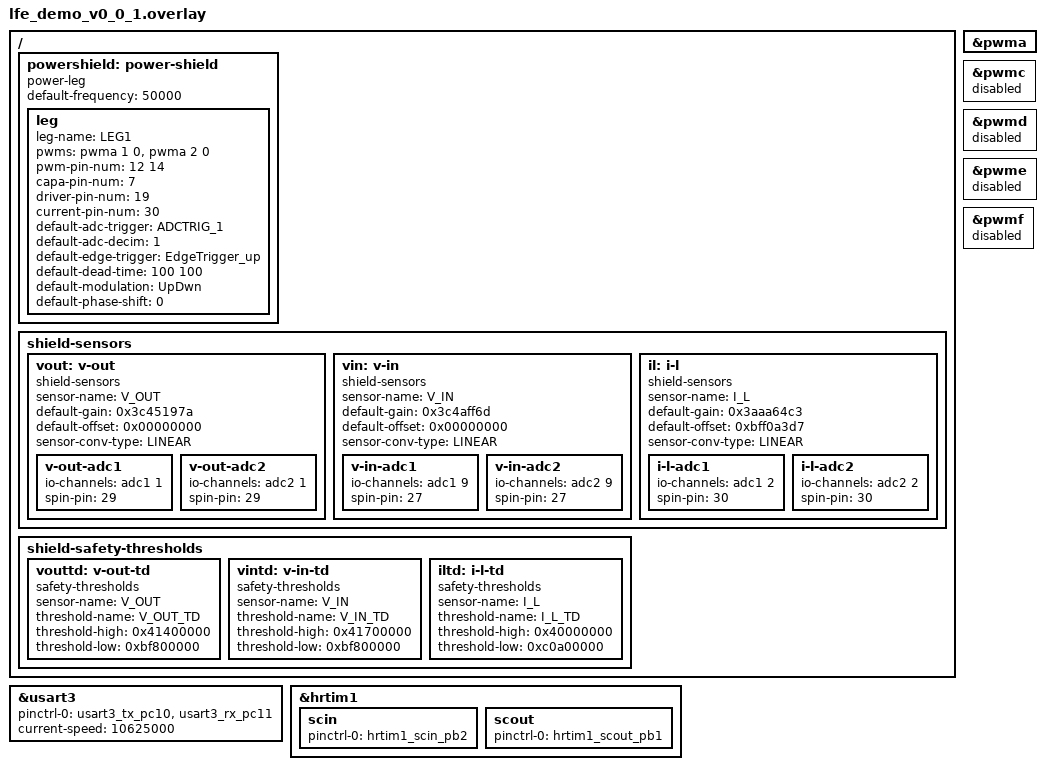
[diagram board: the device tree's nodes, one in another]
/*
 * Copyright (c) 2023-2024 OwnTech.
 *
 * SPDX-License-Identifier: LGPL-2.1
 */

/ {
	powershield: power-shield{
        compatible = "power-leg";
        default-frequency = <50000>;
        leg: leg{
            leg-name = "LEG1";
			pwms = <&pwma 1 0>, <&pwma 2 0>;
            pwm-pin-num = <12 14>;
            capa-pin-num = <7>;
            driver-pin-num = <19>;
            current-pin-num = <30>;
            default-adc-trigger = "ADCTRIG_1";
            default-adc-decim = <1>;
            default-edge-trigger = "EdgeTrigger_up";
            default-dead-time = <100 100>;
            default-modulation = "UpDwn";
            default-phase-shift = <0>;
			status = "okay";
        };

    };

	shield-sensors {
		/* Voltage channels */
		vout: v-out {
			compatible = "shield-sensors";
			sensor-name = "V_OUT";
			default-gain = <0x3c45197a>;
			default-offset = <0x00000000>;
			sensor-conv-type = "LINEAR";
			v-out-adc1 {
				io-channels = <&adc1 1>;
				spin-pin = <29>;
			};
			v-out-adc2 {
				io-channels = <&adc2 1>;
				spin-pin = <29>;
			};
			status = "okay";
		};

		vin: v-in {
			compatible = "shield-sensors";
			sensor-name = "V_IN";
			default-gain = <0x3c4aff6d>;
			default-offset = <0x00000000>;
			sensor-conv-type = "LINEAR";
			v-in-adc1 {
				io-channels = <&adc1 9>;
				spin-pin = <27>;
			};
			v-in-adc2 {
				io-channels = <&adc2 9>;
				spin-pin = <27>;
			};
			status = "okay";
		};

		/* Current sensors */

		il: i-l {
			compatible = "shield-sensors";
			sensor-name = "I_L";
			default-gain = <0x3aaa64c3>;
			default-offset = <0xbff0a3d7>;
			sensor-conv-type = "LINEAR";
			i-l-adc1 {
				io-channels = <&adc1 2>;
				spin-pin = <30>;
			};
			i-l-adc2 {
				io-channels = <&adc2 2>;
				spin-pin = <30>;
			};
			status = "okay";
		};

	};

	shield-safety-thresholds {

		/* Voltage thresholds */

		vouttd: v-out-td {
			compatible = "safety-thresholds";
			sensor-name = "V_OUT";
			threshold-name = "V_OUT_TD";
			threshold-high = <0x41400000>; /* 12.0 */
			threshold-low  = <0xbf800000>; /* -1.0 */
			status = "okay";
		};

		vintd: v-in-td {
			compatible = "safety-thresholds";
			sensor-name = "V_IN";
			threshold-name = "V_IN_TD";
			threshold-high = <0x41700000>; /* 15.0 */
			threshold-low  = <0xbf800000>; /* -1.0 */
			status = "okay";
		};

		iltd: i-l-td {
			compatible = "safety-thresholds";
			sensor-name = "I_L";
			threshold-name = "I_L_TD";
			threshold-high = <0x40000000>; /* 2.0 */
			threshold-low  = <0xc0a00000>; /* -5 */
			status = "okay";
		};

	};
};

// UART / RS485 transceiver

&usart3 {
	pinctrl-0 = < &usart3_tx_pc10 &usart3_rx_pc11 >;
	pinctrl-names = "default";
	current-speed = <10625000>;
	status = "okay";
};


&pwma {
	status = "okay";
};

&pwmc {
	status = "disabled";
};

&pwmd {
	status = "disabled";
};

&pwme {
	status = "disabled";
};

&pwmf {
	status = "disabled";
};

&hrtim1 {
	scin: scin {
		pinctrl-0 = <&hrtim1_scin_pb2>;
	};
	scout: scout {
		pinctrl-0 = <&hrtim1_scout_pb1>;
	};
};
